# PIC32CZ4010CA90208 device description
Architecture: CORTEX-M7; Family: PIC32C; Series: PIC32CZCA90
Registers are 32-bit, read-write, reset 0x0 unless marked. A register's access mark holds for its fields unless they carry their own. Offsets are from the block's base; [hi:lo] are bit positions; {n}, {i} and the like mark numbered series; 'fields as' and 'values as' point back to an identical list; <NAME> marks a mode.

## GCLK — Generic Clock Generator
Instances: GCLK 0x44050000
0x00 CTRLA 8-bit (WSYNC) — Control
  [0] SWRST — Software Reset
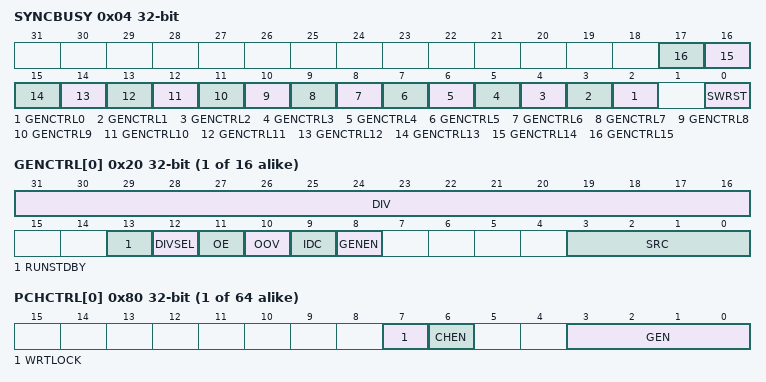
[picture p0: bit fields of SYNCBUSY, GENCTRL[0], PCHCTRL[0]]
0x04 SYNCBUSY ro — Synchronization Busy
  [n+2] GENCTRL{n} (n=0..15) — Generic Clock Generator Control {n} Synchronization Busy bit
  [0] SWRST — Software Reset Synchronization Busy bit
{0x20+4i} GENCTRL[{i}] (i=0..15) (WSYNC) — Generic Clock Generator Control
  [31:16] DIV — Division Factor
  [13] RUNSTDBY — Run in Standby
  [12] DIVSEL — Divide Selection
    0=DIV1 (Divide input directly by divider factor); 1=DIV2 (Divide input by 2^(divider factor+ 1))
  [11] OE — Output Enable
  [10] OOV — Output Off Value
  [9] IDC — Improve Duty Cycle
  [8] GENEN — Generic Clock Generator Enable
  [3:0] SRC — Source Select
    0=XOSC (XOSC0 oscillator output); 1=GCLKIN (Generator input pad); 2=GCLKGEN1 (Generic clock generator 1 output); 3=OSCULP32K (OSCULP32K oscillator output); 4=XOSC32K (XOSC32K oscillator output); 5=DFLL (DFLL output); {v}=PLL0_{v-5} (PLL0 output {v-5}) (v=6..9); 10=PLL1_1 (Frac Divider PLL1 output 1); 11=PLL1_2 (Frac Divider PLL1 output 2); 12=PLL1_3 (PLL1 output 3); 13=PLL1_4 (PLL1 output 4)
{0x80+4i} PCHCTRL[{i}] (i=0..63) — Peripheral Clock Control
  [7] WRTLOCK — Write Lock
  [6] CHEN — Channel Enable
  [3:0] GEN — Generic Clock Generator
    {v}=GCLK{v} (Generic clock generator {v}) (v=0..15)

## HSM — Hardware Security Module
Instances: HSM 0x4F018000
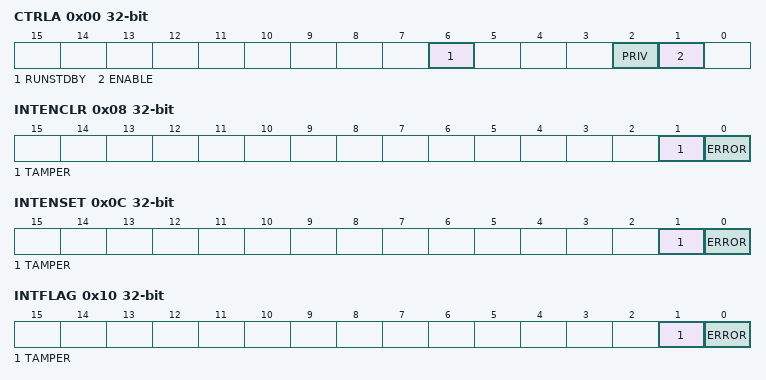
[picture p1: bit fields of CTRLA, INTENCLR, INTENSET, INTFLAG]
0x00 CTRLA — CONTROL REGISTER A
  [6] RUNSTDBY — Run In Standby bit
  [2] PRIV — Privileged Access Only bit
  [1] ENABLE — Clock Enable bit
0x04 CTRLB — CONTROL REGISTER B
  [0] CANCEL — Cancel Command
0x08 INTENCLR (atomic clear) — INTERRUPT ENABLE CLEAR REGISTER
  [1] TAMPER — Tamper Interrupt Enable
  [0] ERROR — Error Interrupt Enable
0x0C INTENSET (atomic set) — INTERRUPT ENABLE SET
  fields as INTENCLR
0x10 INTFLAG (atomic clear) — INTERRUPT FLAG
  [1] TAMPER — Tamper Interrupt Flag
  [0] ERROR — Error Interrupt Flag
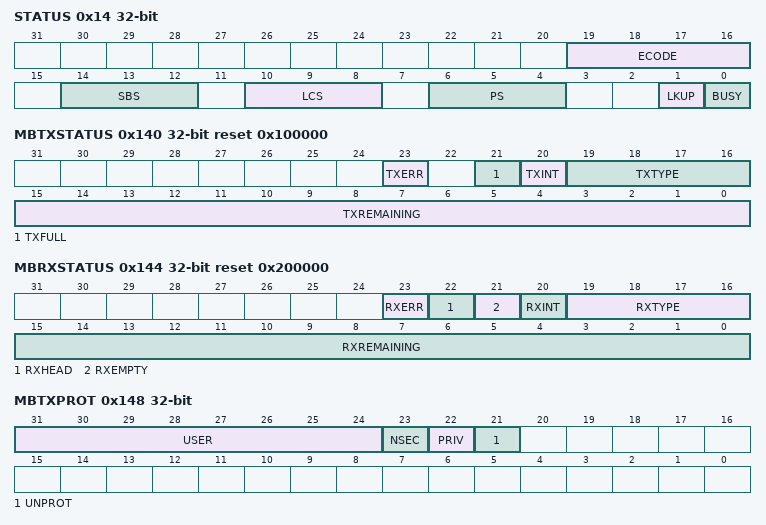
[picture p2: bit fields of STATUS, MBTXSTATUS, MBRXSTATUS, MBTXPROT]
0x14 STATUS
  [19:16] ECODE — ERROR CODE
  [14:12] SBS — SECURE BOOT STATE
  [10:8] LCS — LIFECYCLE STATE
  [6:4] PS — PROCESSING STATE
  [1] LKUP — HSM CPU LOCKUP
  [0] BUSY — HSM CPU BUSY
{0x100+4i} MBFIFO[{i}] (i=0..15) — MAILBOX FIFO
0x140 MBTXSTATUS reset 0x100000 — MAILBOX TRANSMIT STATUS
  [23] TXERR — TRANSMIT ERROR
  [21] TXFULL — TRANSMIT FIFO FULL
  [20] TXINT — TRANSMIT FIFO INTERRUPT FLAG
  [19:16] TXTYPE — TRANSMIT MESSAGE HEADER TYPE
  [15:0] TXREMAINING — TRANSMIT BYTES REMAINING
0x144 MBRXSTATUS reset 0x200000 — MAILBOX RECEIVE STATUS
  [23] RXERR — RECEIVE ERROR
  [22] RXHEAD — Receive Header Next Word bit
  [21] RXEMPTY — RECEIVE FIFO FULL
  [20] RXINT — RECEIVE FIFO INTERRUPT FLAG
  [19:16] RXTYPE — RECEIVE MESSAGE HEADER TYPE
  [15:0] RXREMAINING — RECEIVE BYTES REMAINING
0x148 MBTXPROT — MAILBOX TX PROTECTION
  [31:24] USER — USER SIDEBAND
  [23] NSEC — MAILBOX MESSAGE NON-SECURE ACCESS
  [22] PRIV — MAILBOX MESSAGE PRIVILEDGED ACCESS
  [21] UNPROT — MAILBOX UNPROTECTED
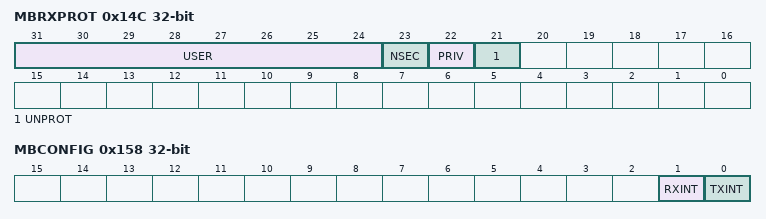
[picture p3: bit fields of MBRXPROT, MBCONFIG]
0x14C MBRXPROT — MAILBOX RX PROTECTION
  fields as MBTXPROT
0x150 MBTXHEAD — MAILBOX TRANSMIT HEADER
  [31:0] TXHEAD — MAILBOX TRANSMIT HEADER REGISTER
0x154 MBRXHEAD — MAILBOX RECEIVE HEADER
  [31:0] RXHEAD — MAILBOX RECEIVE HEADER REGISTER
0x158 MBCONFIG — MAILBOX CONFIGURATION
  [1] RXINT — MAILBOX RECEIVE INTERRUPT ENABLE
  [0] TXINT — MAILBOX TRANSMIT INTERRUPT ENABLE

## ITM — Instrumentation Trace Macrocell
Instances: ITM 0xE0041000
{0x0+4i} PORT[{i}] (i=0..31) wo reset not defined — ITM Stimulus Port Registers
  [7:0] PORT <BYTE>, [15:0] PORT <HWORD>, [31:0] PORT <WORD>
0xE00 TER reset not defined — ITM Trace Enable Register
0xE40 TPR reset not defined — ITM Trace Privilege Register
  [3:0] PRIVMASK
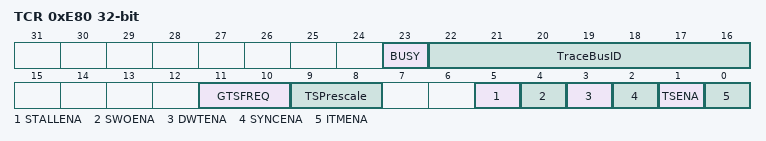
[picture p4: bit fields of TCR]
0xE80 TCR reset not defined — ITM Trace Control Register
  [23] BUSY, [22:16] TraceBusID, [11:10] GTSFREQ, [9:8] TSPrescale, [5] STALLENA, [4] SWOENA, [3] DWTENA, [2] SYNCENA, [1] TSENA, [0] ITMENA
0xEF8 IWR wo reset not defined — ITM Integration Write Register
  [0] ATVALIDM
0xEFC IRR ro reset not defined — ITM Integration Read Register
  [0] ATREADYM

## Notices in the file
Copyright (c) 2021 Microchip Technology Inc.
SPDX-License-Identifier: Apache-2.0
Licensed under the Apache License, Version 2.0 (the "License");
you may not use this file except in compliance with the License.
You may obtain a copy of the License at
http://www.apache.org/licenses/LICENSE-2.0
Unless required by applicable law or agreed to in writing, software
distributed under the License is distributed on an "AS IS" BASIS,
WITHOUT WARRANTIES OR CONDITIONS OF ANY KIND, either express or implied.
See the License for the specific language governing permissions and
limitations under the License.
